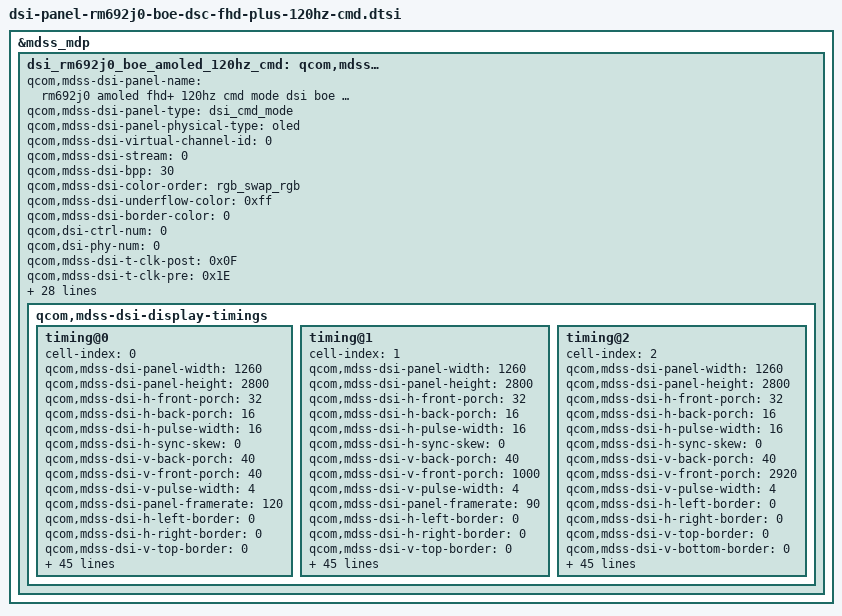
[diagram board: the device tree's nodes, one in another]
//OP Manual


&mdss_mdp {
	dsi_rm692j0_boe_amoled_120hz_cmd:
		qcom,mdss_dsi_rm692j0_120hz_fhd_plus_dsc_cmd {
		qcom,mdss-dsi-panel-name =
			"rm692j0 amoled fhd+ 120hz cmd mode dsi boe panel with DSC";
		qcom,mdss-dsi-panel-type = "dsi_cmd_mode";
		qcom,mdss-dsi-panel-physical-type = "oled";
		qcom,mdss-dsi-virtual-channel-id = <0>;
		qcom,mdss-dsi-stream = <0>;
		qcom,mdss-dsi-bpp = <30>;
		qcom,mdss-dsi-color-order = "rgb_swap_rgb";
		qcom,mdss-dsi-underflow-color = <0xff>;
		qcom,mdss-dsi-border-color = <0>;

		qcom,dsi-ctrl-num = <0>;
		qcom,dsi-phy-num = <0>;
		qcom,mdss-dsi-t-clk-post = <0x0F>;
		qcom,mdss-dsi-t-clk-pre = <0x1E>;

		qcom,mdss-dsi-traffic-mode = "non_burst_sync_event";
		qcom,mdss-dsi-lane-map = "lane_map_0123";
		qcom,mdss-dsi-bllp-eof-power-mode;
		qcom,mdss-dsi-bllp-power-mode;
		qcom,mdss-dsi-lane-0-state;
		qcom,mdss-dsi-lane-1-state;
		qcom,mdss-dsi-lane-2-state;
		qcom,mdss-dsi-lane-3-state;
		qcom,mdss-dsi-dma-trigger = "trigger_sw";
		qcom,mdss-dsi-mdp-trigger = "none";
		qcom,mdss-dsi-lp11-init;
		qcom,mdss-dsi-reset-sequence = <0 0>, <0 0>, <1 32>;
		qcom,mdss-pan-physical-width-dimension = <70>;
		qcom,mdss-pan-physical-height-dimension = <154>;
		qcom,mdss-dsi-tx-eot-append;
		qcom,mdss-dsi-rx-eot-ignore;

		qcom,mdss-dsi-panel-hdr-enabled;
		qcom,mdss-dsi-panel-hdr-color-primaries = <14971 15617 34138
						15863 12979 35519 6814 2450>;
		qcom,mdss-dsi-panel-peak-brightness = <15811641>;
		qcom,mdss-dsi-panel-blackness-level = <1>;

		qcom,mdss-dsi-te-pin-select = <1>;
		qcom,mdss-dsi-wr-mem-start = <0x2c>;
		qcom,mdss-dsi-wr-mem-continue = <0x3c>;
		qcom,mdss-dsi-te-dcs-command = <1>;
		qcom,mdss-dsi-te-check-enable;
		qcom,mdss-dsi-te-using-te-pin;
		qcom,mdss-dsi-display-timings {
			timing@0 {
				cell-index = <0>;
				qcom,mdss-dsi-panel-width = <1260>;
				qcom,mdss-dsi-panel-height = <2800>;
				qcom,mdss-dsi-h-front-porch = <32>;
				qcom,mdss-dsi-h-back-porch = <16>;
				qcom,mdss-dsi-h-pulse-width = <16>;
				qcom,mdss-dsi-h-sync-skew = <0>;
				qcom,mdss-dsi-v-back-porch = <40>;
				qcom,mdss-dsi-v-front-porch = <40>;
				qcom,mdss-dsi-v-pulse-width = <4>;
				qcom,mdss-dsi-panel-framerate = <120>;
				qcom,mdss-dsi-h-left-border = <0>;
				qcom,mdss-dsi-h-right-border = <0>;
				qcom,mdss-dsi-v-top-border = <0>;
				qcom,mdss-dsi-v-bottom-border = <0>;
				qcom,mdss-dsi-panel-jitter = <0x4 0x1>;
				qcom,mdss-dsi-panel-clockrate = <1100000000>;
				qcom,mdss-dsi-timing-switch-command = [
						15 01 00 00 00 00 02 FE 00
						15 01 00 00 00 00 02 2F 00
				];

				qcom,mdss-dsi-on-command = [
						15 01 00 00 00 00 02 FE D2
						15 01 00 00 00 00 02 36 11
						15 01 00 00 00 00 02 39 ab
						15 01 00 00 00 00 02 3A 30
						15 01 00 00 00 00 02 3B 80
						15 01 00 00 00 00 02 3D 0a
						15 01 00 00 00 00 02 3F f0
						15 01 00 00 00 00 02 40 04
						15 01 00 00 00 00 02 41 ec
						15 01 00 00 00 00 02 42 00
						15 01 00 00 00 00 02 43 46
						15 01 00 00 00 00 02 44 02
						15 01 00 00 00 00 02 45 76
						15 01 00 00 00 00 02 46 02
						15 01 00 00 00 00 02 47 76
						15 01 00 00 00 00 02 48 02
						15 01 00 00 00 00 02 49 00
						15 01 00 00 00 00 02 4A 02
						15 01 00 00 00 00 02 4B 3b
						15 01 00 00 00 00 02 4D 20
						15 01 00 00 00 00 02 4E 07
						15 01 00 00 00 00 02 4F 54
						15 01 00 00 00 00 02 50 00
						15 01 00 00 00 00 02 51 08
						15 01 00 00 00 00 02 53 0c
						15 01 00 00 00 00 02 54 01
						15 01 00 00 00 00 02 55 65
						15 01 00 00 00 00 02 56 01
						15 01 00 00 00 00 02 58 3f
						15 01 00 00 00 00 02 59 18
						15 01 00 00 00 00 02 5A 00
						15 01 00 00 00 00 02 5B 10
						15 01 00 00 00 00 02 5C f0
						15 01 00 00 00 00 02 5D 07
						15 01 00 00 00 00 02 5E 10
						15 01 00 00 00 00 02 5F 20
						15 01 00 00 00 00 02 60 00
						15 01 00 00 00 00 02 61 06
						15 01 00 00 00 00 02 62 0f
						15 01 00 00 00 00 02 63 0f
						15 01 00 00 00 00 02 64 33
						15 01 00 00 00 00 02 65 0e
						15 01 00 00 00 00 02 66 1c
						15 01 00 00 00 00 02 67 2a
						15 01 00 00 00 00 02 68 38
						15 01 00 00 00 00 02 69 46
						15 01 00 00 00 00 02 6A 54
						15 01 00 00 00 00 02 6B 62
						15 01 00 00 00 00 02 6C 69
						15 01 00 00 00 00 02 6D 70
						15 01 00 00 00 00 02 6E 77
						15 01 00 00 00 00 02 6F 79
						15 01 00 00 00 00 02 70 7b
						15 01 00 00 00 00 02 71 7d
						15 01 00 00 00 00 02 72 7e
						15 01 00 00 00 00 02 73 01
						15 01 00 00 00 00 02 74 02
						15 01 00 00 00 00 02 75 22
						15 01 00 00 00 00 02 76 00
						15 01 00 00 00 00 02 77 2a
						15 01 00 00 00 00 02 78 40
						15 01 00 00 00 00 02 79 2a
						15 01 00 00 00 00 02 7A be
						15 01 00 00 00 00 02 7B 3a
						15 01 00 00 00 00 02 7C fc
						15 01 00 00 00 00 02 7D 3a
						15 01 00 00 00 00 02 7E fa
						15 01 00 00 00 00 02 7F 3a
						15 01 00 00 00 00 02 80 f8
						15 01 00 00 00 00 02 81 3b
						15 01 00 00 00 00 02 82 38
						15 01 00 00 00 00 02 83 3b
						15 01 00 00 00 00 02 84 78
						15 01 00 00 00 00 02 85 3b
						15 01 00 00 00 00 02 86 b6
						15 01 00 00 00 00 02 87 4b
						15 01 00 00 00 00 02 88 f6
						15 01 00 00 00 00 02 89 4c
						15 01 00 00 00 00 02 8A 36
						15 01 00 00 00 00 02 8B 4c
						15 01 00 00 00 00 02 8C 74
						15 01 00 00 00 00 02 8D 5c
						15 01 00 00 00 00 02 8E 74
						15 01 00 00 00 00 02 8F 8c
						15 01 00 00 00 00 02 90 f4
						15 01 00 00 00 00 02 FE 49
						15 01 00 00 00 00 02 55 55
						15 01 00 00 00 00 02 FE 9B
						15 01 00 00 00 00 02 27 42
						15 01 00 00 00 00 02 FE 36
						15 01 00 00 00 00 02 95 00
						15 01 00 00 00 00 02 96 00
						15 01 00 00 00 00 02 97 00
						15 01 00 00 00 00 02 98 00
						15 01 00 00 00 00 02 99 00
						15 01 00 00 00 00 02 9A 00
						15 01 00 00 00 00 02 7C 10
						15 01 00 00 00 00 02 7D BF
						15 01 00 00 00 00 02 7E 2E
						15 01 00 00 00 00 02 FE 00
						15 01 00 00 00 00 02 73 80
						15 01 00 00 00 00 02 FE 00
						15 01 00 00 00 00 02 FA 01
						15 01 00 00 00 00 02 C2 08
						15 01 00 00 00 00 02 35 00
						39 01 00 00 00 00 03 51 0D BB
						15 01 00 00 00 00 02 FE 62
						15 01 00 00 00 00 02 4B AF
						15 01 00 00 00 00 02 4C FE
						15 01 00 00 00 00 02 4D FF
						15 01 00 00 00 00 02 4E 55
						15 01 00 00 00 00 02 4F AF
						15 01 00 00 00 00 02 84 FE
						15 01 00 00 00 00 02 FE 60
						15 01 00 00 00 00 02 F9 55
						15 01 00 00 00 00 02 FE 9B
						15 01 00 00 00 00 02 00 66
						15 01 00 00 00 00 02 01 66
						15 01 00 00 00 00 02 02 66
						15 01 00 00 00 00 02 03 66
						15 01 00 00 00 00 02 04 66
						15 01 00 00 00 00 02 05 66
						15 01 00 00 00 00 02 FE 00
						15 01 00 00 00 00 02 2F 00
						05 01 00 00 50 00 01 11
						05 01 00 00 0A 00 01 29];
				qcom,mdss-dsi-off-command = [
						15 01 00 00 00 00 02 FE 00
						05 01 00 00 50 00 01 28
						05 01 00 00 64 00 01 10];
				qcom,mdss-dsi-on-command-state = "dsi_lp_mode";
				qcom,mdss-dsi-off-command-state = "dsi_hs_mode";
				qcom,mdss-dsi-timing-switch-command-state =
					"dsi_lp_mode";

				qcom,mdss-dsi-switch-aod1-command = [
						05 01 00 00 00 00 01 39
						39 01 00 00 00 00 03 51 0F FF];
				qcom,mdss-dsi-switch-aod1-command-state = "dsi_lp_mode";

				qcom,mdss-dsi-switch-aod2-command = [
						05 01 00 00 00 00 01 39
						39 01 00 00 00 00 03 51 0B 2E];
				qcom,mdss-dsi-switch-aod2-command-state = "dsi_lp_mode";

				qcom,mdss-dsi-switch-aod3-command = [
						05 01 00 00 00 00 01 39
						39 01 00 00 00 00 03 51 00 10];
				qcom,mdss-dsi-switch-aod3-command-state = "dsi_lp_mode";

				qcom,mdss-dsi-nolp-command = [
						05 01 00 00 00 00 01 38];
				qcom,mdss-dsi-nolp-command-state = "dsi_lp_mode";

				qcom,mdss-dsi-lhbm-on-command = [
					15 01 00 00 00 00 02 2F 07
					15 01 00 00 00 00 02 FE 42
					15 01 00 00 00 00 02 82 00
					15 01 00 00 00 00 02 83 00
					15 01 00 00 00 00 02 FE 00
					15 01 00 00 00 00 02 83 01];
				qcom,mdss-dsi-lhbm-on-command-state = "dsi_lp_mode";
				qcom,mdss-dsi-lhbm-off-command = [
					15 01 00 00 00 00 02 FE 00
					15 01 00 00 00 00 02 83 00
					15 01 00 00 00 00 02 2F 00];
				qcom,mdss-dsi-lhbm-off-command-state = "dsi_lp_mode";

				qcom,mdss-dsi-h-sync-pulse = <0>;
				qcom,compression-mode = "dsc";
				qcom,mdss-dsc-rc-override_v1;
				qcom,mdss-dsc-slice-height = <70>;
				qcom,mdss-dsc-slice-width = <630>;
				qcom,mdss-dsc-slice-per-pkt = <2>;
				qcom,mdss-dsc-bit-per-component = <10>;
				qcom,mdss-dsc-bit-per-pixel = <8>;
				qcom,mdss-dsc-block-prediction-enable;
			};
			timing@1 {
				cell-index = <1>;
				qcom,mdss-dsi-panel-width = <1260>;
				qcom,mdss-dsi-panel-height = <2800>;
				qcom,mdss-dsi-h-front-porch = <32>;
				qcom,mdss-dsi-h-back-porch = <16>;
				qcom,mdss-dsi-h-pulse-width = <16>;
				qcom,mdss-dsi-h-sync-skew = <0>;
				qcom,mdss-dsi-v-back-porch = <40>;
				qcom,mdss-dsi-v-front-porch = <1000>;
				qcom,mdss-dsi-v-pulse-width = <4>;
				qcom,mdss-dsi-panel-framerate = <90>;
				qcom,mdss-dsi-h-left-border = <0>;
				qcom,mdss-dsi-h-right-border = <0>;
				qcom,mdss-dsi-v-top-border = <0>;
				qcom,mdss-dsi-v-bottom-border = <0>;
				qcom,mdss-dsi-panel-jitter = <0x4 0x1>;
				qcom,mdss-dsi-panel-clockrate = <1100000000>;
				qcom,mdss-dsi-timing-switch-command = [
						15 01 00 00 00 00 02 FE 00
						15 01 00 00 00 00 02 2F 05
				];

				qcom,mdss-dsi-on-command = [
						15 01 00 00 00 00 02 FE D2
						15 01 00 00 00 00 02 36 11
						15 01 00 00 00 00 02 39 ab
						15 01 00 00 00 00 02 3A 30
						15 01 00 00 00 00 02 3B 80
						15 01 00 00 00 00 02 3D 0a
						15 01 00 00 00 00 02 3F f0
						15 01 00 00 00 00 02 40 04
						15 01 00 00 00 00 02 41 ec
						15 01 00 00 00 00 02 42 00
						15 01 00 00 00 00 02 43 46
						15 01 00 00 00 00 02 44 02
						15 01 00 00 00 00 02 45 76
						15 01 00 00 00 00 02 46 02
						15 01 00 00 00 00 02 47 76
						15 01 00 00 00 00 02 48 02
						15 01 00 00 00 00 02 49 00
						15 01 00 00 00 00 02 4A 02
						15 01 00 00 00 00 02 4B 3b
						15 01 00 00 00 00 02 4D 20
						15 01 00 00 00 00 02 4E 07
						15 01 00 00 00 00 02 4F 54
						15 01 00 00 00 00 02 50 00
						15 01 00 00 00 00 02 51 08
						15 01 00 00 00 00 02 53 0c
						15 01 00 00 00 00 02 54 01
						15 01 00 00 00 00 02 55 65
						15 01 00 00 00 00 02 56 01
						15 01 00 00 00 00 02 58 3f
						15 01 00 00 00 00 02 59 18
						15 01 00 00 00 00 02 5A 00
						15 01 00 00 00 00 02 5B 10
						15 01 00 00 00 00 02 5C f0
						15 01 00 00 00 00 02 5D 07
						15 01 00 00 00 00 02 5E 10
						15 01 00 00 00 00 02 5F 20
						15 01 00 00 00 00 02 60 00
						15 01 00 00 00 00 02 61 06
						15 01 00 00 00 00 02 62 0f
						15 01 00 00 00 00 02 63 0f
						15 01 00 00 00 00 02 64 33
						15 01 00 00 00 00 02 65 0e
						15 01 00 00 00 00 02 66 1c
						15 01 00 00 00 00 02 67 2a
						15 01 00 00 00 00 02 68 38
						15 01 00 00 00 00 02 69 46
						15 01 00 00 00 00 02 6A 54
						15 01 00 00 00 00 02 6B 62
						15 01 00 00 00 00 02 6C 69
						15 01 00 00 00 00 02 6D 70
						15 01 00 00 00 00 02 6E 77
						15 01 00 00 00 00 02 6F 79
						15 01 00 00 00 00 02 70 7b
						15 01 00 00 00 00 02 71 7d
						15 01 00 00 00 00 02 72 7e
						15 01 00 00 00 00 02 73 01
						15 01 00 00 00 00 02 74 02
						15 01 00 00 00 00 02 75 22
						15 01 00 00 00 00 02 76 00
						15 01 00 00 00 00 02 77 2a
						15 01 00 00 00 00 02 78 40
						15 01 00 00 00 00 02 79 2a
						15 01 00 00 00 00 02 7A be
						15 01 00 00 00 00 02 7B 3a
						15 01 00 00 00 00 02 7C fc
						15 01 00 00 00 00 02 7D 3a
						15 01 00 00 00 00 02 7E fa
						15 01 00 00 00 00 02 7F 3a
						15 01 00 00 00 00 02 80 f8
						15 01 00 00 00 00 02 81 3b
						15 01 00 00 00 00 02 82 38
						15 01 00 00 00 00 02 83 3b
						15 01 00 00 00 00 02 84 78
						15 01 00 00 00 00 02 85 3b
						15 01 00 00 00 00 02 86 b6
						15 01 00 00 00 00 02 87 4b
						15 01 00 00 00 00 02 88 f6
						15 01 00 00 00 00 02 89 4c
						15 01 00 00 00 00 02 8A 36
						15 01 00 00 00 00 02 8B 4c
						15 01 00 00 00 00 02 8C 74
						15 01 00 00 00 00 02 8D 5c
						15 01 00 00 00 00 02 8E 74
						15 01 00 00 00 00 02 8F 8c
						15 01 00 00 00 00 02 90 f4
						15 01 00 00 00 00 02 FE 49
						15 01 00 00 00 00 02 55 55
						15 01 00 00 00 00 02 FE 9B
						15 01 00 00 00 00 02 27 42
						15 01 00 00 00 00 02 FE 36
						15 01 00 00 00 00 02 95 00
						15 01 00 00 00 00 02 96 00
						15 01 00 00 00 00 02 97 00
						15 01 00 00 00 00 02 98 00
						15 01 00 00 00 00 02 99 00
						15 01 00 00 00 00 02 9A 00
						15 01 00 00 00 00 02 7C 10
						15 01 00 00 00 00 02 7D BF
						15 01 00 00 00 00 02 7E 2E
						15 01 00 00 00 00 02 FE 00
						15 01 00 00 00 00 02 73 80
						15 01 00 00 00 00 02 FE 00
						15 01 00 00 00 00 02 FA 01
						15 01 00 00 00 00 02 C2 08
						15 01 00 00 00 00 02 35 00
						39 01 00 00 00 00 03 51 0D BB
						15 01 00 00 00 00 02 FE 62
						15 01 00 00 00 00 02 4B AF
						15 01 00 00 00 00 02 4C FE
						15 01 00 00 00 00 02 4D FF
						15 01 00 00 00 00 02 4E 55
						15 01 00 00 00 00 02 4F AF
						15 01 00 00 00 00 02 84 FE
						15 01 00 00 00 00 02 FE 60
						15 01 00 00 00 00 02 F9 55
						15 01 00 00 00 00 02 FE 9B
						15 01 00 00 00 00 02 00 66
						15 01 00 00 00 00 02 01 66
						15 01 00 00 00 00 02 02 66
						15 01 00 00 00 00 02 03 66
						15 01 00 00 00 00 02 04 66
						15 01 00 00 00 00 02 05 66
						15 01 00 00 00 00 02 FE 00
						15 01 00 00 00 00 02 2F 05
						05 01 00 00 50 00 01 11
						05 01 00 00 0A 00 01 29];
				qcom,mdss-dsi-off-command = [
						15 01 00 00 00 00 02 FE 00
						05 01 00 00 50 00 01 28
						05 01 00 00 64 00 01 10];
				qcom,mdss-dsi-on-command-state = "dsi_lp_mode";
				qcom,mdss-dsi-off-command-state = "dsi_hs_mode";
				qcom,mdss-dsi-timing-switch-command-state =
					"dsi_lp_mode";

				qcom,mdss-dsi-switch-aod1-command = [
						05 01 00 00 00 00 01 39
						39 01 00 00 00 00 03 51 0F FF];
				qcom,mdss-dsi-switch-aod1-command-state = "dsi_lp_mode";

				qcom,mdss-dsi-switch-aod2-command = [
						05 01 00 00 00 00 01 39
						39 01 00 00 00 00 03 51 0B 2E];
				qcom,mdss-dsi-switch-aod2-command-state = "dsi_lp_mode";

				qcom,mdss-dsi-switch-aod3-command = [
						05 01 00 00 00 00 01 39
						39 01 00 00 00 00 03 51 00 10];
				qcom,mdss-dsi-switch-aod3-command-state = "dsi_lp_mode";

				qcom,mdss-dsi-nolp-command = [
						05 01 00 00 00 00 01 38];
				qcom,mdss-dsi-nolp-command-state = "dsi_lp_mode";

				qcom,mdss-dsi-lhbm-on-command = [
					15 01 00 00 00 00 02 2F 07
					15 01 00 00 00 00 02 FE 42
					15 01 00 00 00 00 02 82 00
					15 01 00 00 00 00 02 83 00
					15 01 00 00 00 00 02 FE 00
					15 01 00 00 00 00 02 83 01];
				qcom,mdss-dsi-lhbm-on-command-state = "dsi_lp_mode";
				qcom,mdss-dsi-lhbm-off-command = [
					15 01 00 00 00 00 02 FE 00
					15 01 00 00 00 00 02 83 00
					15 01 00 00 00 00 02 2F 00];
				qcom,mdss-dsi-lhbm-off-command-state = "dsi_lp_mode";

				qcom,mdss-dsi-h-sync-pulse = <0>;
				qcom,compression-mode = "dsc";
				qcom,mdss-dsc-rc-override_v1;
				qcom,mdss-dsc-slice-height = <70>;
				qcom,mdss-dsc-slice-width = <630>;
				qcom,mdss-dsc-slice-per-pkt = <2>;
				qcom,mdss-dsc-bit-per-component = <10>;
				qcom,mdss-dsc-bit-per-pixel = <8>;
				qcom,mdss-dsc-block-prediction-enable;
			};
			timing@2 {
				cell-index = <2>;
				qcom,mdss-dsi-panel-width = <1260>;
				qcom,mdss-dsi-panel-height = <2800>;
				qcom,mdss-dsi-h-front-porch = <32>;
				qcom,mdss-dsi-h-back-porch = <16>;
				qcom,mdss-dsi-h-pulse-width = <16>;
				qcom,mdss-dsi-h-sync-skew = <0>;
				qcom,mdss-dsi-v-back-porch = <40>;
				qcom,mdss-dsi-v-front-porch = <2920>;
				qcom,mdss-dsi-v-pulse-width = <4>;
				qcom,mdss-dsi-h-left-border = <0>;
				qcom,mdss-dsi-h-right-border = <0>;
				qcom,mdss-dsi-v-top-border = <0>;
				qcom,mdss-dsi-v-bottom-border = <0>;
				qcom,mdss-dsi-panel-jitter = <0x4 0x1>;
				qcom,mdss-dsi-panel-clockrate = <1100000000>;
				qcom,mdss-dsi-panel-framerate = <60>;
				qcom,mdss-dsi-timing-switch-command = [
						15 01 00 00 00 00 02 FE 00
						15 01 00 00 00 00 02 2F 06
				];

				qcom,mdss-dsi-on-command = [
						15 01 00 00 00 00 02 FE D2
						15 01 00 00 00 00 02 36 11
						15 01 00 00 00 00 02 39 ab
						15 01 00 00 00 00 02 3A 30
						15 01 00 00 00 00 02 3B 80
						15 01 00 00 00 00 02 3D 0a
						15 01 00 00 00 00 02 3F f0
						15 01 00 00 00 00 02 40 04
						15 01 00 00 00 00 02 41 ec
						15 01 00 00 00 00 02 42 00
						15 01 00 00 00 00 02 43 46
						15 01 00 00 00 00 02 44 02
						15 01 00 00 00 00 02 45 76
						15 01 00 00 00 00 02 46 02
						15 01 00 00 00 00 02 47 76
						15 01 00 00 00 00 02 48 02
						15 01 00 00 00 00 02 49 00
						15 01 00 00 00 00 02 4A 02
						15 01 00 00 00 00 02 4B 3b
						15 01 00 00 00 00 02 4D 20
						15 01 00 00 00 00 02 4E 07
						15 01 00 00 00 00 02 4F 54
						15 01 00 00 00 00 02 50 00
						15 01 00 00 00 00 02 51 08
						15 01 00 00 00 00 02 53 0c
						15 01 00 00 00 00 02 54 01
						15 01 00 00 00 00 02 55 65
						15 01 00 00 00 00 02 56 01
						15 01 00 00 00 00 02 58 3f
						15 01 00 00 00 00 02 59 18
						15 01 00 00 00 00 02 5A 00
						15 01 00 00 00 00 02 5B 10
						15 01 00 00 00 00 02 5C f0
						15 01 00 00 00 00 02 5D 07
						15 01 00 00 00 00 02 5E 10
						15 01 00 00 00 00 02 5F 20
						15 01 00 00 00 00 02 60 00
						15 01 00 00 00 00 02 61 06
						15 01 00 00 00 00 02 62 0f
						15 01 00 00 00 00 02 63 0f
						15 01 00 00 00 00 02 64 33
						15 01 00 00 00 00 02 65 0e
						15 01 00 00 00 00 02 66 1c
						15 01 00 00 00 00 02 67 2a
						15 01 00 00 00 00 02 68 38
						15 01 00 00 00 00 02 69 46
						15 01 00 00 00 00 02 6A 54
						15 01 00 00 00 00 02 6B 62
						15 01 00 00 00 00 02 6C 69
						15 01 00 00 00 00 02 6D 70
						15 01 00 00 00 00 02 6E 77
						15 01 00 00 00 00 02 6F 79
						15 01 00 00 00 00 02 70 7b
						15 01 00 00 00 00 02 71 7d
						15 01 00 00 00 00 02 72 7e
						15 01 00 00 00 00 02 73 01
						15 01 00 00 00 00 02 74 02
						15 01 00 00 00 00 02 75 22
						15 01 00 00 00 00 02 76 00
						15 01 00 00 00 00 02 77 2a
						15 01 00 00 00 00 02 78 40
						15 01 00 00 00 00 02 79 2a
						15 01 00 00 00 00 02 7A be
						15 01 00 00 00 00 02 7B 3a
						15 01 00 00 00 00 02 7C fc
						15 01 00 00 00 00 02 7D 3a
						15 01 00 00 00 00 02 7E fa
						15 01 00 00 00 00 02 7F 3a
						15 01 00 00 00 00 02 80 f8
						15 01 00 00 00 00 02 81 3b
						15 01 00 00 00 00 02 82 38
						15 01 00 00 00 00 02 83 3b
						15 01 00 00 00 00 02 84 78
						15 01 00 00 00 00 02 85 3b
						15 01 00 00 00 00 02 86 b6
						15 01 00 00 00 00 02 87 4b
						15 01 00 00 00 00 02 88 f6
						15 01 00 00 00 00 02 89 4c
						15 01 00 00 00 00 02 8A 36
						15 01 00 00 00 00 02 8B 4c
						15 01 00 00 00 00 02 8C 74
						15 01 00 00 00 00 02 8D 5c
						15 01 00 00 00 00 02 8E 74
						15 01 00 00 00 00 02 8F 8c
						15 01 00 00 00 00 02 90 f4
						15 01 00 00 00 00 02 FE 49
						15 01 00 00 00 00 02 55 55
						15 01 00 00 00 00 02 FE 9B
						15 01 00 00 00 00 02 27 42
						15 01 00 00 00 00 02 FE 36
						15 01 00 00 00 00 02 95 00
						15 01 00 00 00 00 02 96 00
						15 01 00 00 00 00 02 97 00
						15 01 00 00 00 00 02 98 00
						15 01 00 00 00 00 02 99 00
						15 01 00 00 00 00 02 9A 00
						15 01 00 00 00 00 02 7C 10
						15 01 00 00 00 00 02 7D BF
						15 01 00 00 00 00 02 7E 2E
						15 01 00 00 00 00 02 FE 00
						15 01 00 00 00 00 02 73 80
						15 01 00 00 00 00 02 FE 00
						15 01 00 00 00 00 02 FA 01
						15 01 00 00 00 00 02 C2 08
						15 01 00 00 00 00 02 35 00
						39 01 00 00 00 00 03 51 0D BB
						15 01 00 00 00 00 02 FE 62
						15 01 00 00 00 00 02 4B AF
						15 01 00 00 00 00 02 4C FE
						15 01 00 00 00 00 02 4D FF
						15 01 00 00 00 00 02 4E 55
						15 01 00 00 00 00 02 4F AF
						15 01 00 00 00 00 02 84 FE
						15 01 00 00 00 00 02 FE 60
						15 01 00 00 00 00 02 F9 55
						15 01 00 00 00 00 02 FE 9B
						15 01 00 00 00 00 02 00 66
						15 01 00 00 00 00 02 01 66
						15 01 00 00 00 00 02 02 66
						15 01 00 00 00 00 02 03 66
						15 01 00 00 00 00 02 04 66
						15 01 00 00 00 00 02 05 66
						15 01 00 00 00 00 02 FE 00
						15 01 00 00 00 00 02 2F 06
						05 01 00 00 50 00 01 11
						05 01 00 00 0A 00 01 29];
				qcom,mdss-dsi-off-command = [
						15 01 00 00 00 00 02 FE 00
						05 01 00 00 50 00 01 28
						05 01 00 00 64 00 01 10];
				qcom,mdss-dsi-on-command-state = "dsi_lp_mode";
				qcom,mdss-dsi-off-command-state = "dsi_hs_mode";
				qcom,mdss-dsi-timing-switch-command-state =
					"dsi_lp_mode";

				qcom,mdss-dsi-switch-aod1-command = [
						05 01 00 00 00 00 01 39
						39 01 00 00 00 00 03 51 0F FF];
				qcom,mdss-dsi-switch-aod1-command-state = "dsi_lp_mode";

				qcom,mdss-dsi-switch-aod2-command = [
						05 01 00 00 00 00 01 39
						39 01 00 00 00 00 03 51 0B 2E];
				qcom,mdss-dsi-switch-aod2-command-state = "dsi_lp_mode";

				qcom,mdss-dsi-switch-aod3-command = [
						05 01 00 00 00 00 01 39
						39 01 00 00 00 00 03 51 00 10];
				qcom,mdss-dsi-switch-aod3-command-state = "dsi_lp_mode";

				qcom,mdss-dsi-nolp-command = [
						05 01 00 00 00 00 01 38];
				qcom,mdss-dsi-nolp-command-state = "dsi_lp_mode";

				qcom,mdss-dsi-lhbm-on-command = [
					15 01 00 00 00 00 02 2F 07
					15 01 00 00 00 00 02 FE 42
					15 01 00 00 00 00 02 82 00
					15 01 00 00 00 00 02 83 00
					15 01 00 00 00 00 02 FE 00
					15 01 00 00 00 00 02 83 01];
				qcom,mdss-dsi-lhbm-on-command-state = "dsi_lp_mode";
				qcom,mdss-dsi-lhbm-off-command = [
					15 01 00 00 00 00 02 FE 00
					15 01 00 00 00 00 02 83 00
					15 01 00 00 00 00 02 2F 00];
				qcom,mdss-dsi-lhbm-off-command-state = "dsi_lp_mode";

				qcom,mdss-dsi-h-sync-pulse = <0>;
				qcom,compression-mode = "dsc";
				qcom,mdss-dsc-rc-override_v1;
				qcom,mdss-dsc-slice-height = <70>;
				qcom,mdss-dsc-slice-width = <630>;
				qcom,mdss-dsc-slice-per-pkt = <2>;
				qcom,mdss-dsc-bit-per-component = <10>;
				qcom,mdss-dsc-bit-per-pixel = <8>;
				qcom,mdss-dsc-block-prediction-enable;
			};
		};
	};
};
